# M3U0 register map
File version: 0.1
Registers are 32-bit, read-write, no defined reset value unless marked. A register's access mark holds for its fields unless they carry their own. Offsets are from the block's base; [hi:lo] are bit positions; {n}, {i} and the like mark numbered series.

## PG — General Purpose Input_Output Port (PG)
Base 0x40000180
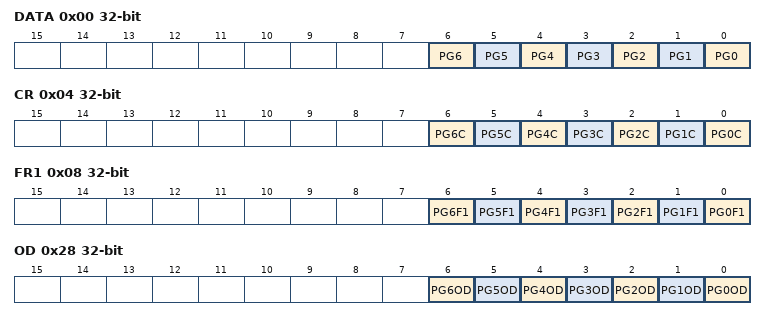
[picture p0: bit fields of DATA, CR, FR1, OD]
0x00 DATA — PG Register
  [n] PG{n} (n=0..6)
0x04 CR — PG Control Register
  [n] PG{n}C (n=0..6)
0x08 FR1 — PG Function Register 1
  [n] PG{n}F1 (n=0..6)
0x0C FR2 — PG Function Register 2
  [6] PG6F2
0x28 OD — PG Open Drain Control Register
  [n] PG{n}OD (n=0..6)
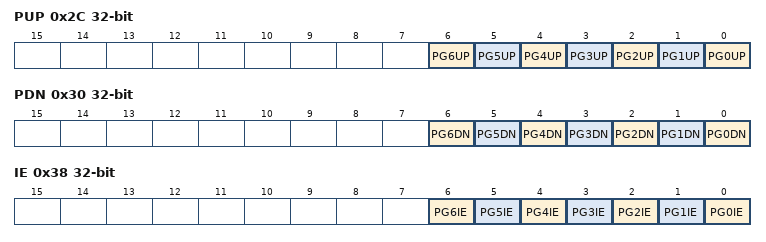
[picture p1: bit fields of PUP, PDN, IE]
0x2C PUP — PG Pull-Up Control Register
  [n] PG{n}UP (n=0..6)
0x30 PDN — PG Pull-Down Control Register
  [n] PG{n}DN (n=0..6)
0x38 IE — PG Input Enable Control Register
  [n] PG{n}IE (n=0..6)

## PJ — General Purpose Input_Output Port (PJ)
Base 0x40000240
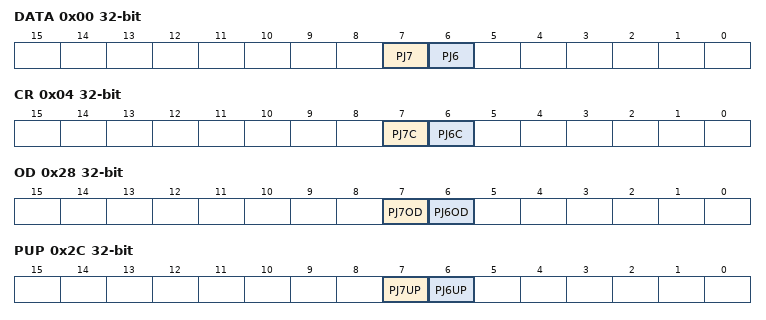
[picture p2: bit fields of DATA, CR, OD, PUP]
0x00 DATA — PJ Register
  [7] PJ7, [6] PJ6
0x04 CR — PJ Control Register
  [7] PJ7C, [6] PJ6C
0x28 OD — PJ Open Drain Control Register
  [7] PJ7OD, [6] PJ6OD
0x2C PUP — PJ Pull-Up Control Register
  [7] PJ7UP, [6] PJ6UP
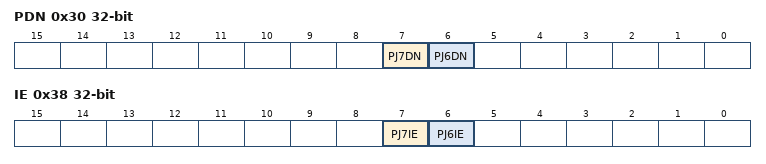
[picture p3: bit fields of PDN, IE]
0x30 PDN — PJ Pull-Down Control Register
  [7] PJ7DN, [6] PJ6DN
0x38 IE — PJ Input Enable Control Register
  [7] PJ7IE, [6] PJ6IE

## PK — General Purpose Input_Output Port (PK)
Base 0x40000280
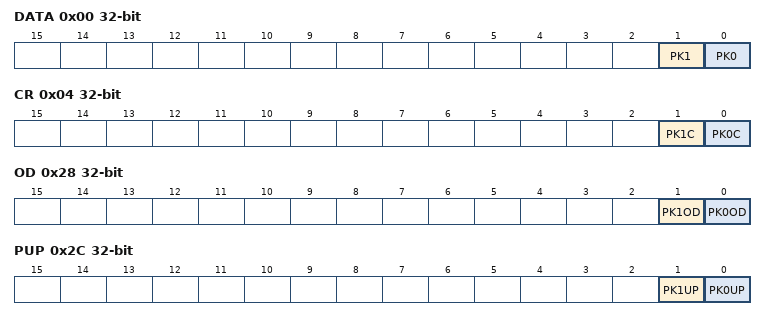
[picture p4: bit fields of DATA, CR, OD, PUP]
0x00 DATA — PK Register
  [1] PK1, [0] PK0
0x04 CR — PK Control Register
  [1] PK1C, [0] PK0C
0x28 OD — PK Open Drain Control Register
  [1] PK1OD, [0] PK0OD
0x2C PUP — PK Pull-Up Control Register
  [1] PK1UP, [0] PK0UP
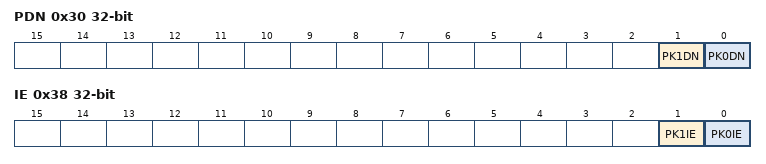
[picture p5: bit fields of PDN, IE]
0x30 PDN — PK Pull-Down Control Register
  [1] PK1DN, [0] PK0DN
0x38 IE — PK Input Enable Control Register
  [1] PK1IE, [0] PK0IE

## PM — General Purpose Input_Output Port (PM)
Base 0x40000300
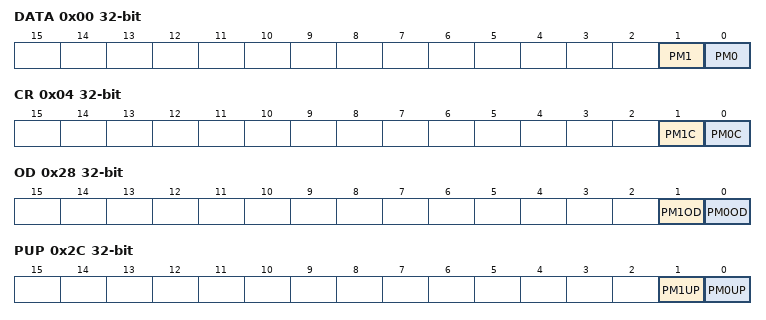
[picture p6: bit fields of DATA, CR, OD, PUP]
0x00 DATA — PM Register
  [1] PM1, [0] PM0
0x04 CR — PM Control Register
  [1] PM1C, [0] PM0C
0x28 OD — PM Open Drain Control Register
  [1] PM1OD, [0] PM0OD
0x2C PUP — PM Pull-Up Control Register
  [1] PM1UP, [0] PM0UP
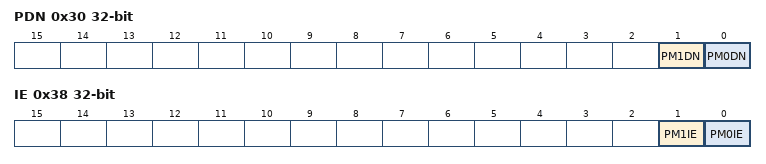
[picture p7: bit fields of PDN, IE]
0x30 PDN — PM Pull-Down Control Register
  [1] PM1DN, [0] PM0DN
0x38 IE — PM Input Enable Control Register
  [1] PM1IE, [0] PM0IE

## TB0 — 16-bit Timer_Event Counter (TB)
Base 0x40010000
Same registers: TB4 0x40010100, TB5 0x40010140, TB7 0x400101C0
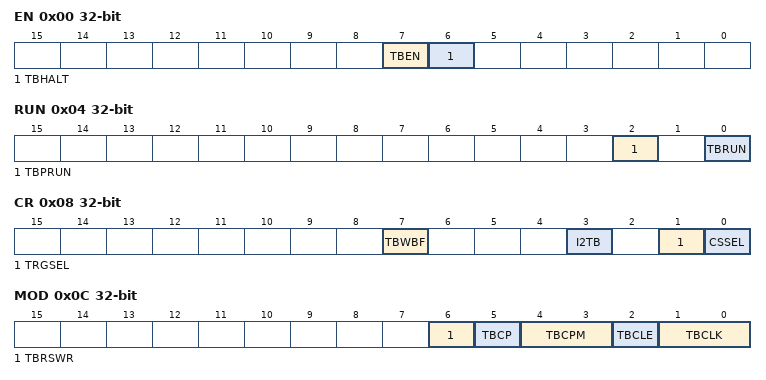
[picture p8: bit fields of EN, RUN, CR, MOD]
0x00 EN — TB Enable Register
  [7] TBEN, [6] TBHALT
0x04 RUN — TB RUN Register
  [2] TBPRUN, [0] TBRUN
0x08 CR — TB Control Register
  [7] TBWBF, [3] I2TB, [1] TRGSEL, [0] CSSEL
0x0C MOD — TB Mode Register
  [6] TBRSWR, [5] TBCP wo, [4:3] TBCPM, [2] TBCLE, [1:0] TBCLK
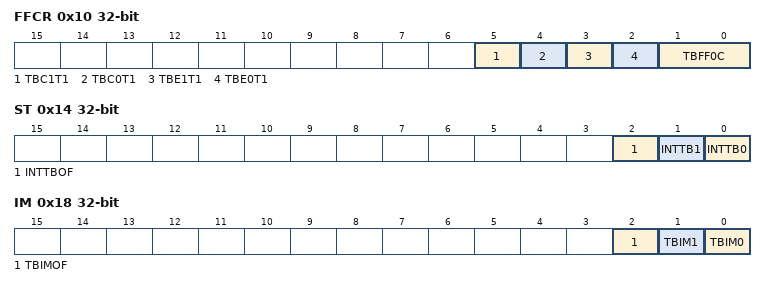
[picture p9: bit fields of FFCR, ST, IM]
0x10 FFCR — TB Flip-Flop Control Register
  [5] TBC1T1, [4] TBC0T1, [3] TBE1T1, [2] TBE0T1, [1:0] TBFF0C
0x14 ST ro — TB Status Register
  [2] INTTBOF, [1] INTTB1, [0] INTTB0
0x18 IM — TB Interrupt Mask Register
  [2] TBIMOF, [1] TBIM1, [0] TBIM0
0x1C UC ro — TB Read Capture Register
  [15:0] UC
0x20 RG0 — TB RG0 Timer Register
  [15:0] TBRG0
0x24 RG1 — TB RG1 Timer Register
  [15:0] TBRG1
0x28 CP0 ro — TB CP0 Capture Register
  [15:0] TBCP0
0x2C CP1 ro — TB CP1 Capture Register
  [15:0] TBCP1

## EN — Encoder Input (ENC)
Base 0x40010400
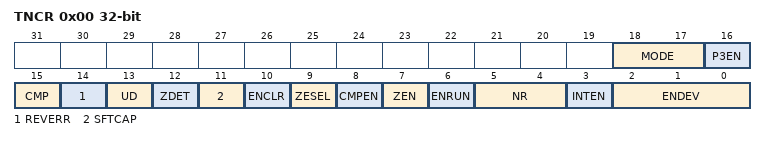
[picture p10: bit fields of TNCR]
0x00 TNCR — Encoder Input Control Register
  [18:17] MODE, [16] P3EN, [15] CMP ro, [14] REVERR ro, [13] UD ro, [12] ZDET ro, [11] SFTCAP wo, [10] ENCLR wo, [9] ZESEL, [8] CMPEN, [7] ZEN, [6] ENRUN, [5:4] NR, [3] INTEN, [2:0] ENDEV
0x04 RELOAD — Encoder Counter Reload Register
  [15:0] RELOAD
0x08 INT — Encoder Compare Register
  [23:0] INT
0x0C CNT — Encoder Counter Register
  [23:0] CNT

## SBI — Serial BusInterface(SBI)
Base 0x40020000
0x00 CR0 — SBI Control Register 0
  [7] SBIEN
0x04 CR1_A — SBI Control Register 1 (I2C Mode)
  [7:5] BC, [4] ACK, [0] SWRMON ro, [2:0] SCK wo
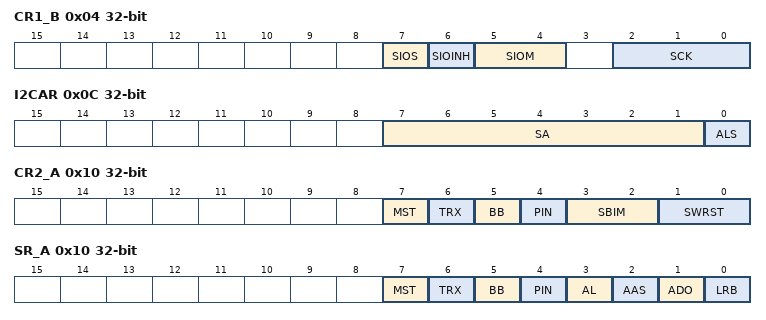
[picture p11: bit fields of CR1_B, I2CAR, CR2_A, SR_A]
0x04 CR1_B (SBI_CR1 view) — SBI Control Register 1 (SIO Mode)
  [7] SIOS, [6] SIOINH, [5:4] SIOM, [2:0] SCK
0x08 DBR — SBI Data Buffer Register
  [7:0] DB
0x0C I2CAR — SBI I2C Bus Address Register
  [7:1] SA, [0] ALS
0x10 CR2_A wo — SBI Control Register 2 (I2C Mode)
  [7] MST, [6] TRX, [5] BB, [4] PIN, [3:2] SBIM, [1:0] SWRST
0x10 CR2_B wo (SBI_CR2 view) — SBI Control Register 2 (SIO Mode)
  [3:2] SBIM
0x10 SR_A ro — SBI Status Register (I2C Mode)
  [7] MST, [6] TRX, [5] BB, [4] PIN, [3] AL, [2] AAS, [1] ADO, [0] LRB
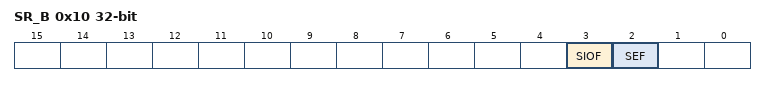
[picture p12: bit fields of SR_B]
0x10 SR_B ro (SBI_SR view) — SBI Status Register (SIO Mode)
  [3] SIOF, [2] SEF
0x14 BR0 — SBI Baud Rate Register 0
  [6] I2SBI
